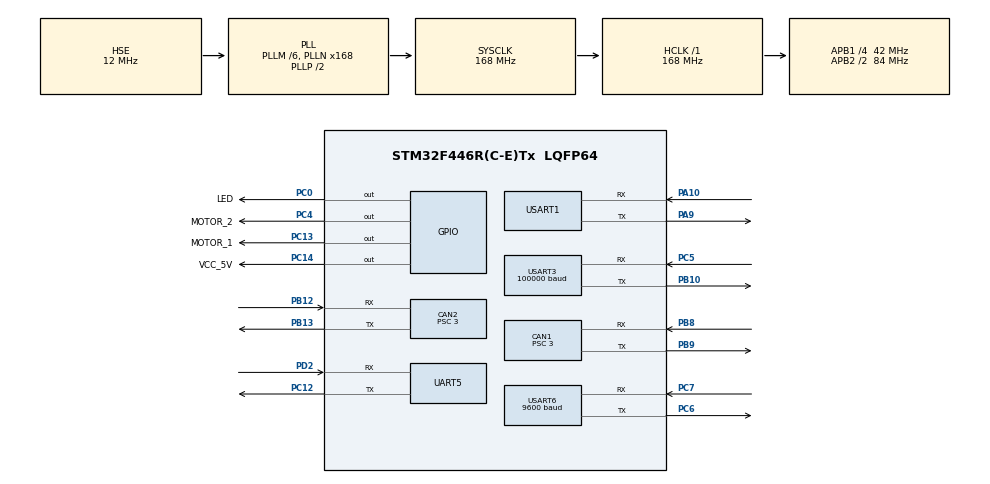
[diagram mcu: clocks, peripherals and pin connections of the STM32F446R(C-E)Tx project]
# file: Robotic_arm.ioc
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CAN1.BS1=CAN_BS1_10TQ
CAN1.BS2=CAN_BS2_3TQ
CAN1.CalculateBaudRate=1000000
CAN1.CalculateTimeBit=1000
CAN1.CalculateTimeQuantum=71.42857142857143
CAN1.Prescaler=3
CAN2.BS1=CAN_BS1_10TQ
CAN2.BS2=CAN_BS2_3TQ
CAN2.CalculateBaudRate=1000000
CAN2.CalculateTimeBit=1000
CAN2.CalculateTimeQuantum=71.42857142857143
CAN2.Prescaler=3
Dma.Request0=USART1_TX
Dma.Request1=USART3_RX
Dma.USART1_TX.0.Direction=DMA_MEMORY_TO_PERIPH
Dma.USART1_TX.0.FIFOMode=DMA_FIFOMODE_DISABLE
Dma.USART1_TX.0.Instance=DMA2_Stream7
Dma.USART1_TX.0.MemDataAlignment=DMA_MDATAALIGN_BYTE
Dma.USART1_TX.0.MemInc=DMA_MINC_ENABLE
Dma.USART1_TX.0.Mode=DMA_NORMAL
Dma.USART1_TX.0.PeriphDataAlignment=DMA_PDATAALIGN_BYTE
Dma.USART1_TX.0.PeriphInc=DMA_PINC_DISABLE
Dma.USART1_TX.0.Priority=DMA_PRIORITY_VERY_HIGH
Dma.USART3_RX.1.Direction=DMA_PERIPH_TO_MEMORY
Dma.USART3_RX.1.FIFOMode=DMA_FIFOMODE_DISABLE
Dma.USART3_RX.1.Instance=DMA1_Stream1
Dma.USART3_RX.1.MemDataAlignment=DMA_MDATAALIGN_BYTE
Dma.USART3_RX.1.MemInc=DMA_MINC_ENABLE
Dma.USART3_RX.1.Mode=DMA_NORMAL
Dma.USART3_RX.1.PeriphDataAlignment=DMA_PDATAALIGN_BYTE
Dma.USART3_RX.1.PeriphInc=DMA_PINC_DISABLE
Dma.USART3_RX.1.Priority=DMA_PRIORITY_VERY_HIGH
FREERTOS.Tasks01=defaultTask,0,128,StartDefaultTask,Default,NULL,Dynamic,NULL,NULL;ARM_TASK,2,128,arm_task,As external,NULL,Dynamic,NULL,NULL
Mcu.Family=STM32F4
Mcu.Name=STM32F446R(C-E)Tx
Mcu.Package=LQFP64
NVIC.CAN1_RX0_IRQn=true\:5\:0\:false\:false\:true\:true\:true\:true\:true
NVIC.DMA1_Stream1_IRQn=true\:5\:0\:false\:false\:true\:true\:false\:true\:true
NVIC.DMA2_Stream7_IRQn=true\:5\:0\:false\:false\:true\:true\:false\:true\:true
NVIC.PriorityGroup=NVIC_PRIORITYGROUP_4
NVIC.UART5_IRQn=true\:5\:0\:false\:false\:true\:true\:true\:true\:true
NVIC.USART3_IRQn=true\:5\:0\:false\:false\:true\:true\:true\:true\:true
NVIC.USART6_IRQn=true\:5\:0\:false\:false\:true\:true\:true\:true\:true
PA10.Mode=Asynchronous
PA10.Signal=USART1_RX
PA13.Mode=Serial_Wire
PA13.Signal=SYS_JTMS-SWDIO
PA14.Mode=Serial_Wire
PA14.Signal=SYS_JTCK-SWCLK
PA9.Mode=Asynchronous
PA9.Signal=USART1_TX
PB10.Mode=Asynchronous
PB10.Signal=USART3_TX
PB12.Mode=CAN_Activate
PB12.Signal=CAN2_RX
PB13.Mode=CAN_Activate
PB13.Signal=CAN2_TX
PB8.Mode=CAN_Activate
PB8.Signal=CAN1_RX
PB9.Mode=CAN_Activate
PB9.Signal=CAN1_TX
PC0.GPIO_Label=LED
PC0.GPIO_PuPd=GPIO_NOPULL
PC0.Signal=GPIO_Output
PC12.Mode=Asynchronous
PC12.Signal=UART5_TX
PC13.GPIO_Label=MOTOR_1
PC13.PinState=GPIO_PIN_SET
PC13.Signal=GPIO_Output
PC14-OSC32_IN.GPIO_Label=VCC_5V
PC14-OSC32_IN.GPIO_PuPd=GPIO_NOPULL
PC14-OSC32_IN.Signal=GPIO_Output
PC4.GPIO_Label=MOTOR_2
PC4.PinState=GPIO_PIN_SET
PC4.Signal=GPIO_Output
PC5.Mode=Asynchronous
PC5.Signal=USART3_RX
PC6.Mode=Asynchronous
PC6.Signal=USART6_TX
PC7.Mode=Asynchronous
PC7.Signal=USART6_RX
PD2.Mode=Asynchronous
PD2.Signal=UART5_RX
PH0-OSC_IN.Mode=HSE-External-Oscillator
PH0-OSC_IN.Signal=RCC_OSC_IN
PH1-OSC_OUT.Mode=HSE-External-Oscillator
PH1-OSC_OUT.Signal=RCC_OSC_OUT
ProjectManager.HeapSize=0x200
ProjectManager.StackSize=0x400
ProjectManager.TargetToolchain=MDK-ARM V5.32
RCC.AHBFreq_Value=168000000
RCC.APB1CLKDivider=RCC_HCLK_DIV4
RCC.APB1Freq_Value=42000000
RCC.APB1TimFreq_Value=84000000
RCC.APB2CLKDivider=RCC_HCLK_DIV2
RCC.APB2Freq_Value=84000000
RCC.APB2TimFreq_Value=168000000
RCC.CortexFreq_Value=168000000
RCC.HCLKFreq_Value=168000000
RCC.HSE_VALUE=12000000
RCC.PLLM=6
RCC.PLLN=168
RCC.PLLSAIM=6
RCC.PLLSAIN=96
RCC.PLLSourceVirtual=RCC_PLLSOURCE_HSE
RCC.SYSCLKFreq_VALUE=168000000
RCC.SYSCLKSource=RCC_SYSCLKSOURCE_PLLCLK
RCC.USBFreq_Value=168000000
RCC.VCOOutputFreq_Value=336000000
UART5.VirtualMode=Asynchronous
USART1.VirtualMode=VM_ASYNC
USART3.BaudRate=100000
USART3.VirtualMode=VM_ASYNC
USART6.BaudRate=9600
USART6.VirtualMode=VM_ASYNC
VP_FREERTOS_VS_CMSIS_V1.Mode=CMSIS_V1
board=custom

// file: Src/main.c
/* USER CODE BEGIN Header */
/**
  ******************************************************************************
  * @file           : main.c
  * @brief          : Main program body
  ******************************************************************************
  * @attention
  *
  * Copyright (c) 2023 STMicroelectronics.
  * All rights reserved.
  *
  * This software is licensed under terms that can be found in the LICENSE file
  * in the root directory of this software component.
  * If no LICENSE file comes with this software, it is provided AS-IS.
  *
  ******************************************************************************
  */
/* USER CODE END Header */
#include "main.h"
#include "cmsis_os.h"
#include "can.h"
#include "dma.h"
#include "usart.h"
#include "gpio.h"

/* USER CODE BEGIN Includes */
#include "Can_user.h"
#include "remote_control.h"
#include "Uart_user.h"

/* USER CODE END Includes */

void SystemClock_Config(void);
void MX_FREERTOS_Init(void);

int main(void)
{

  /* MCU Configuration--------------------------------------------------------*/

  /* Reset of all peripherals, Initializes the Flash interface and the Systick. */
  HAL_Init();

  /* Configure the system clock */
  SystemClock_Config();

  /* Initialize all configured peripherals */
  MX_GPIO_Init();
  MX_DMA_Init();
  MX_CAN1_Init();
  MX_CAN2_Init();
  MX_USART1_UART_Init();
  MX_USART3_UART_Init();
  MX_UART5_Init();
  MX_USART6_UART_Init();
  /* USER CODE BEGIN 2 */
	can_filter_init();
	data_receive_IT();
	remote_control_init();
  /* USER CODE END 2 */

  /* Call init function for freertos objects (in freertos.c) */
  MX_FREERTOS_Init();

  /* Start scheduler */
  osKernelStart();

  /* We should never get here as control is now taken by the scheduler */
  /* Infinite loop */
  while (1)
  {

  }
}

void SystemClock_Config(void)
{
  RCC_OscInitTypeDef RCC_OscInitStruct = {0};
  RCC_ClkInitTypeDef RCC_ClkInitStruct = {0};

  /** Configure the main internal regulator output voltage
  */
  __HAL_RCC_PWR_CLK_ENABLE();
  __HAL_PWR_VOLTAGESCALING_CONFIG(PWR_REGULATOR_VOLTAGE_SCALE1);

  /** Initializes the RCC Oscillators according to the specified parameters
  * in the RCC_OscInitTypeDef structure.
  */
  RCC_OscInitStruct.OscillatorType = RCC_OSCILLATORTYPE_HSE;
  RCC_OscInitStruct.HSEState = RCC_HSE_ON;
  RCC_OscInitStruct.PLL.PLLState = RCC_PLL_ON;
  RCC_OscInitStruct.PLL.PLLSource = RCC_PLLSOURCE_HSE;
  RCC_OscInitStruct.PLL.PLLM = 6;
  RCC_OscInitStruct.PLL.PLLN = 168;
  RCC_OscInitStruct.PLL.PLLP = RCC_PLLP_DIV2;
  RCC_OscInitStruct.PLL.PLLQ = 2;
  RCC_OscInitStruct.PLL.PLLR = 2;
  if (HAL_RCC_OscConfig(&RCC_OscInitStruct) != HAL_OK)
  {
    Error_Handler();
  }

  /** Initializes the CPU, AHB and APB buses clocks
  */
  RCC_ClkInitStruct.ClockType = RCC_CLOCKTYPE_HCLK|RCC_CLOCKTYPE_SYSCLK
                              |RCC_CLOCKTYPE_PCLK1|RCC_CLOCKTYPE_PCLK2;
  RCC_ClkInitStruct.SYSCLKSource = RCC_SYSCLKSOURCE_PLLCLK;
  RCC_ClkInitStruct.AHBCLKDivider = RCC_SYSCLK_DIV1;
  RCC_ClkInitStruct.APB1CLKDivider = RCC_HCLK_DIV4;
  RCC_ClkInitStruct.APB2CLKDivider = RCC_HCLK_DIV2;

  if (HAL_RCC_ClockConfig(&RCC_ClkInitStruct, FLASH_LATENCY_5) != HAL_OK)
  {
    Error_Handler();
  }
}

void Error_Handler(void)
{
  __disable_irq();
  while (1)
  {
  }
}

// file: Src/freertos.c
/* USER CODE BEGIN Header */
/**
  ******************************************************************************
  * File Name          : freertos.c
  * Description        : Code for freertos applications
  ******************************************************************************
  * @attention
  *
  * Copyright (c) 2023 STMicroelectronics.
  * All rights reserved.
  *
  * This software is licensed under terms that can be found in the LICENSE file
  * in the root directory of this software component.
  * If no LICENSE file comes with this software, it is provided AS-IS.
  *
  ******************************************************************************
  */
/* USER CODE END Header */

#include "FreeRTOS.h"
#include "task.h"
#include "main.h"
#include "cmsis_os.h"

/* USER CODE BEGIN Includes */
#include "Arm_Task.h"
/* USER CODE END Includes */

osThreadId defaultTaskHandle;
osThreadId ARM_TASKHandle;

void StartDefaultTask(void const * argument);
extern void arm_task(void const * argument);

void MX_FREERTOS_Init(void); /* (MISRA C 2004 rule 8.1) */

/* GetIdleTaskMemory prototype (linked to static allocation support) */
void vApplicationGetIdleTaskMemory( StaticTask_t **ppxIdleTaskTCBBuffer, StackType_t **ppxIdleTaskStackBuffer, uint32_t *pulIdleTaskStackSize );

/* USER CODE BEGIN GET_IDLE_TASK_MEMORY */
static StaticTask_t xIdleTaskTCBBuffer;
static StackType_t xIdleStack[configMINIMAL_STACK_SIZE];

void vApplicationGetIdleTaskMemory( StaticTask_t **ppxIdleTaskTCBBuffer, StackType_t **ppxIdleTaskStackBuffer, uint32_t *pulIdleTaskStackSize )
{
  *ppxIdleTaskTCBBuffer = &xIdleTaskTCBBuffer;
  *ppxIdleTaskStackBuffer = &xIdleStack[0];
  *pulIdleTaskStackSize = configMINIMAL_STACK_SIZE;
  /* place for user code */
}
/* USER CODE END GET_IDLE_TASK_MEMORY */

void MX_FREERTOS_Init(void) {

  /* Create the thread(s) */
  /* definition and creation of defaultTask */
  osThreadDef(defaultTask, StartDefaultTask, osPriorityNormal, 0, 128);
  defaultTaskHandle = osThreadCreate(osThread(defaultTask), NULL);

  /* definition and creation of ARM_TASK */
  osThreadDef(ARM_TASK, arm_task, osPriorityHigh, 0, 128);
  ARM_TASKHandle = osThreadCreate(osThread(ARM_TASK), NULL);

}

void StartDefaultTask(void const * argument)
{
  for(;;)
  {
    osDelay(1);
  }
}
